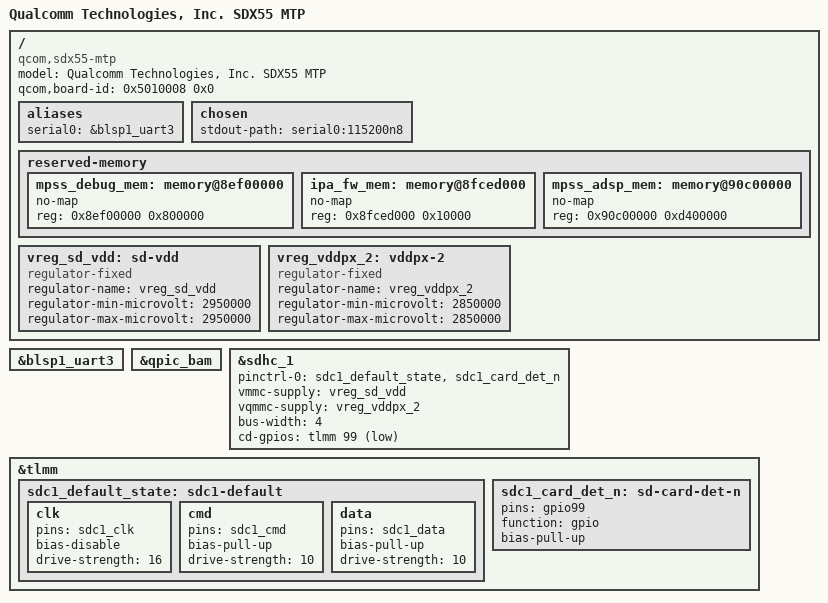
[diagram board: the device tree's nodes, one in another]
// SPDX-License-Identifier: BSD-3-Clause
/*
 * Copyright (c) 2018-2020, The Linux Foundation. All rights reserved.
 * Copyright (c) 2020, Linaro Ltd.
 */

/dts-v1/;

#include <dt-bindings/gpio/gpio.h>
#include "qcom-sdx55.dtsi"

/ {
	model = "Qualcomm Technologies, Inc. SDX55 MTP";
	compatible = "qcom,sdx55-mtp", "qcom,sdx55";
	qcom,board-id = <0x5010008 0x0>;

	aliases {
		serial0 = &blsp1_uart3;
	};

	chosen {
		stdout-path = "serial0:115200n8";
	};

	reserved-memory {
		#address-cells = <1>;
		#size-cells = <1>;
		ranges;

		mpss_debug_mem: memory@8ef00000 {
			no-map;
			reg = <0x8ef00000 0x800000>;
		};

		ipa_fw_mem: memory@8fced000 {
			no-map;
			reg = <0x8fced000 0x10000>;
		};

		mpss_adsp_mem: memory@90c00000 {
			no-map;
			reg = <0x90c00000 0xd400000>;
		};
	};

	vreg_sd_vdd: sd-vdd {
		compatible = "regulator-fixed";
		regulator-name = "vreg_sd_vdd";
		regulator-min-microvolt = <2950000>;
		regulator-max-microvolt = <2950000>;
	};

	vreg_vddpx_2: vddpx-2 {
		compatible = "regulator-fixed";
		regulator-name = "vreg_vddpx_2";
		regulator-min-microvolt = <2850000>;
		regulator-max-microvolt = <2850000>;
	};
};

&blsp1_uart3 {
	status = "ok";
};

&qpic_bam {
	status = "ok";
};

&sdhc_1 {
	pinctrl-names = "default";
	pinctrl-0 = <&sdc1_default_state &sdc1_card_det_n>;
	vmmc-supply = <&vreg_sd_vdd>;
	vqmmc-supply = <&vreg_vddpx_2>;
	bus-width = <4>;
	cd-gpios = <&tlmm 99 GPIO_ACTIVE_LOW>;
	status = "ok";
};

&tlmm {
	sdc1_default_state: sdc1-default {
		clk {
			pins = "sdc1_clk";
			bias-disable;
			drive-strength = <16>;
		};

		cmd {
			pins = "sdc1_cmd";
			bias-pull-up;
			drive-strength = <10>;
		};

		data {
			pins = "sdc1_data";
			bias-pull-up;
			drive-strength = <10>;
		};
	};

	sdc1_card_det_n: sd-card-det-n {
		pins = "gpio99";
		function = "gpio";
		bias-pull-up;
	};
};
